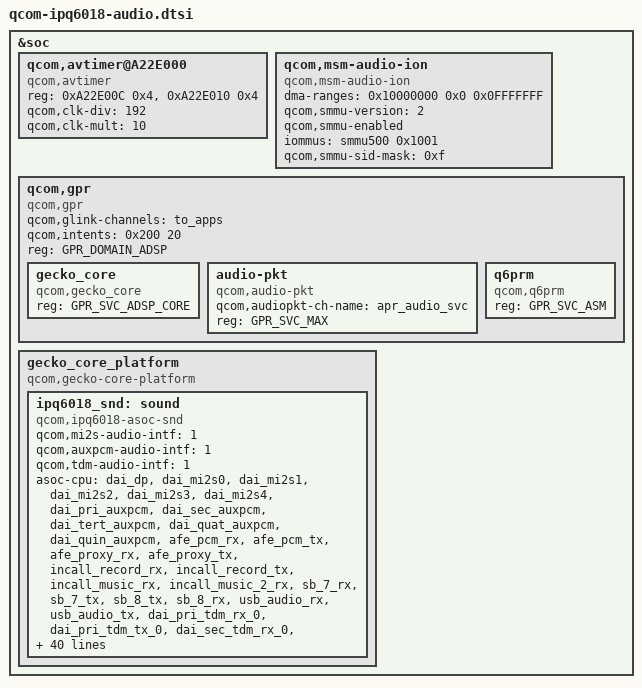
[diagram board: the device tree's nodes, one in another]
/*
 * Copyright (c) 2019, The Linux Foundation. All rights reserved.
 *
 * This program is free software; you can redistribute it and/or modify
 * it under the terms of the GNU General Public License version 2 and
 * only version 2 as published by the Free Software Foundation.
 *
 * This program is distributed in the hope that it will be useful,
 * but WITHOUT ANY WARRANTY; without even the implied warranty of
 * MERCHANTABILITY or FITNESS FOR A PARTICULAR PURPOSE.  See the
 * GNU General Public License for more details.
 */


#include <dt-bindings/clock/qcom,audio-ext-clk.h>
#include "msm-audio-lpass.dtsi"
#include <dt-bindings/sound/qcom,gpr.h>

&soc {
	qcom,avtimer@A22E000 {
		compatible = "qcom,avtimer";
		reg = <0xA22E00C 0x4>,
		      <0xA22E010 0x4>;
		reg-names = "avtimer_lsb_addr", "avtimer_msb_addr";
		qcom,clk-div = <192>;
		qcom,clk-mult = <10>;
	};

	qcom,msm-audio-ion {
		compatible = "qcom,msm-audio-ion";
		ranges;
		dma-ranges = <0x10000000 0x0 0x0FFFFFFF>;
		qcom,smmu-version = <2>;
		qcom,smmu-enabled;
		iommus = <&smmu500 0x1001>;
		qcom,smmu-sid-mask = /bits/ 64 <0xf>;
	};

	qcom,gpr {
		compatible = "qcom,gpr";
		qcom,glink-channels = "to_apps";
		qcom,intents = <0x200 20>;
		#address-cells = <1>;
		#size-cells = <0>;
		reg = <GPR_DOMAIN_ADSP>;
		gecko_core {
			compatible = "qcom,gecko_core";
			reg = <GPR_SVC_ADSP_CORE>;
		};
		audio-pkt {
			compatible = "qcom,audio-pkt";
			qcom,audiopkt-ch-name = "apr_audio_svc";
			reg = <GPR_SVC_MAX>;
		};
		q6prm {
			compatible = "qcom,q6prm";
			reg = <GPR_SVC_ASM>;
		};
	};

	gecko_core_platform: gecko_core_platform {
		compatible = "qcom,gecko-core-platform";
	};
};

&gecko_core_platform {
	ipq6018_snd: sound {
		compatible = "qcom,ipq6018-asoc-snd";
		qcom,mi2s-audio-intf = <1>;
		qcom,auxpcm-audio-intf = <1>;
		qcom,tdm-audio-intf = <1>;

		asoc-cpu = <&dai_dp>,
				<&dai_mi2s0>, <&dai_mi2s1>,
				<&dai_mi2s2>, <&dai_mi2s3>,
				<&dai_mi2s4>, <&dai_pri_auxpcm>,
				<&dai_sec_auxpcm>, <&dai_tert_auxpcm>,
				<&dai_quat_auxpcm>, <&dai_quin_auxpcm>,
				<&afe_pcm_rx>, <&afe_pcm_tx>, <&afe_proxy_rx>,
				<&afe_proxy_tx>, <&incall_record_rx>,
				<&incall_record_tx>, <&incall_music_rx>,
				<&incall_music_2_rx>,
				<&sb_7_rx>, <&sb_7_tx>, <&sb_8_tx>, <&sb_8_rx>,
				<&usb_audio_rx>, <&usb_audio_tx>,
				<&dai_pri_tdm_rx_0>, <&dai_pri_tdm_tx_0>,
				<&dai_sec_tdm_rx_0>, <&dai_sec_tdm_tx_0>,
				<&dai_tert_tdm_rx_0>, <&dai_tert_tdm_tx_0>,
				<&dai_quat_tdm_rx_0>, <&dai_quat_tdm_tx_0>,
				<&dai_quin_tdm_rx_0>, <&dai_quin_tdm_tx_0>,
				<&wsa_cdc_dma_0_rx>, <&wsa_cdc_dma_0_tx>,
				<&wsa_cdc_dma_1_rx>, <&wsa_cdc_dma_1_tx>,
				<&wsa_cdc_dma_2_tx>,
				<&tx_cdc_dma_0_tx>,
				<&tx_cdc_dma_1_tx>,
				<&tx_cdc_dma_2_tx>,
				<&tx_cdc_dma_3_tx>,
				<&tx_cdc_dma_4_tx>,
				<&tx_cdc_dma_5_tx>,
				<&rx_cdc_dma_7_rx>;
		asoc-cpu-names = "msm-dai-q6-dp.24608",
				"msm-dai-q6-mi2s.0", "msm-dai-q6-mi2s.1",
				"msm-dai-q6-mi2s.2", "msm-dai-q6-mi2s.3",
				"msm-dai-q6-mi2s.4", "msm-dai-q6-auxpcm.1",
				"msm-dai-q6-auxpcm.2", "msm-dai-q6-auxpcm.3",
				"msm-dai-q6-auxpcm.4", "msm-dai-q6-auxpcm.5",
				"msm-dai-q6-dev.224",
				"msm-dai-q6-dev.225", "msm-dai-q6-dev.241",
				"msm-dai-q6-dev.240", "msm-dai-q6-dev.32771",
				"msm-dai-q6-dev.32772", "msm-dai-q6-dev.32773",
				"msm-dai-q6-dev.32770", "msm-dai-q6-dev.16398",
				"msm-dai-q6-dev.16399", "msm-dai-q6-dev.16401",
				"msm-dai-q6-dev.16400",
				"msm-dai-q6-dev.28672", "msm-dai-q6-dev.28673",
				"msm-dai-q6-tdm.36864", "msm-dai-q6-tdm.36865",
				"msm-dai-q6-tdm.36880", "msm-dai-q6-tdm.36881",
				"msm-dai-q6-tdm.36896", "msm-dai-q6-tdm.36897",
				"msm-dai-q6-tdm.36912", "msm-dai-q6-tdm.36913",
				"msm-dai-q6-tdm.36928", "msm-dai-q6-tdm.36929",
				"msm-dai-cdc-dma-dev.45056",
				"msm-dai-cdc-dma-dev.45057",
				"msm-dai-cdc-dma-dev.45058",
				"msm-dai-cdc-dma-dev.45059",
				"msm-dai-cdc-dma-dev.45061",
				"msm-dai-cdc-dma-dev.45111",
				"msm-dai-cdc-dma-dev.45112",
				"msm-dai-cdc-dma-dev.45113",
				"msm-dai-cdc-dma-dev.45114",
				"msm-dai-cdc-dma-dev.45115",
				"msm-dai-cdc-dma-dev.45116",
				"msm-dai-cdc-dma-dev.45118";
	};
};
